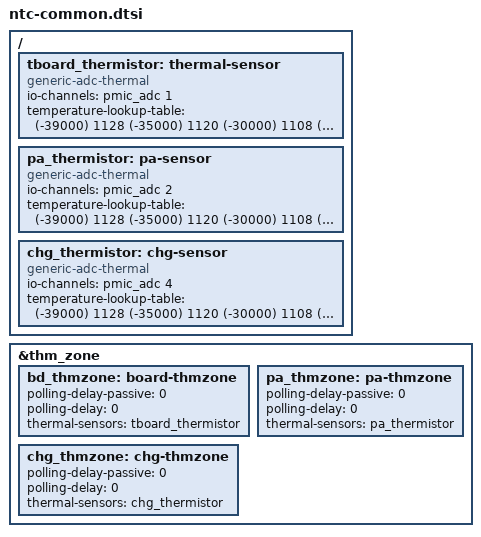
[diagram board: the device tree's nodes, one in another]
/ {
	tboard_thermistor:thermal-sensor {
		compatible = "generic-adc-thermal";
		#thermal-sensor-cells = <0>;
		io-channels = <&pmic_adc 1>;
		io-channel-names = "sensor-channel";
		temperature-lookup-table = <
					(-39000) 1128
					(-35000) 1120
					(-30000) 1108
					(-28000) 1103
					(-26000) 1097
					(-24000) 1089
					(-22000) 1082
					(-20000) 1073
					(-18000) 1064
					(-16000) 1054
					(-14000) 1043
					(-12000) 1032
					(-10000) 1019
					(-9000) 1012
					(-8000) 1005
					(-7000) 998
					(-6000) 990
					(-5000) 983
					(-4000) 975
					(-3000) 966
					(-2000) 957
					(-1000) 949
					0000 940
					1000 931
					2000 921
					3000 912
					4000 902
					5000 891
					6000 881
					7000 870
					8000 855
					9000 845
					10000 834
					11000 823
					12000 811
					13000 799
					14000 788
					15000 776
					16000 764
					17000 751
					18000 740
					19000 727
					20000 715
					21000 704
					22000 692
					23000 679
					24000 665
					25000 652
					26000 639
					27000 626
					28000 614
					29000 601
					30000 589
					31000 577
					32000 564
					33000 552
					34000 539
					35000 527
					36000 515
					37000 503
					38000 491
					39000 480
					40000 468
					41000 457
					42000 446
					43000 518
					44000 423
					45000 412
					46000 401
					47000 391
					48000 381
					49000 371
					50000 361
					51000 351
					52000 342
					53000 333
					54000 324
					55000 315
					56000 306
					57000 297
					58000 289
					59000 281
					60000 273
					61000 265
					62000 258
					63000 251
					64000 243
					65000 237
					66000 230
					67000 223
					68000 217
					69000 211
					70000 205
					74000 182
					78000 162
					82000 144
					86000 128
					90000 114
					94000 102
					98000 91
					102000 81
					106000 72
					110000 65
					114000 58
					118000 52
					122000 47
					125000 43 >;
	};

	pa_thermistor: pa-sensor {
		compatible = "generic-adc-thermal";
		#thermal-sensor-cells = <0>;
		io-channels = <&pmic_adc 2>;
		io-channel-names = "sensor-channel";
		temperature-lookup-table = <
					(-39000) 1128
					(-35000) 1120
					(-30000) 1108
					(-28000) 1103
					(-26000) 1097
					(-24000) 1089
					(-22000) 1082
					(-20000) 1073
					(-18000) 1064
					(-16000) 1054
					(-14000) 1043
					(-12000) 1032
					(-10000) 1019
					(-9000) 1012
					(-8000) 1005
					(-7000) 998
					(-6000) 990
					(-5000) 983
					(-4000) 975
					(-3000) 966
					(-2000) 957
					(-1000) 949
					0000 940
					1000 931
					2000 921
					3000 912
					4000 902
					5000 891
					6000 881
					7000 870
					8000 855
					9000 845
					10000 834
					11000 823
					12000 811
					13000 799
					14000 788
					15000 776
					16000 764
					17000 751
					18000 740
					19000 727
					20000 715
					21000 704
					22000 692
					23000 679
					24000 665
					25000 652
					26000 639
					27000 626
					28000 614
					29000 601
					30000 589
					31000 577
					32000 564
					33000 552
					34000 539
					35000 527
					36000 515
					37000 503
					38000 491
					39000 480
					40000 468
					41000 457
					42000 446
					43000 518
					44000 423
					45000 412
					46000 401
					47000 391
					48000 381
					49000 371
					50000 361
					51000 351
					52000 342
					53000 333
					54000 324
					55000 315
					56000 306
					57000 297
					58000 289
					59000 281
					60000 273
					61000 265
					62000 258
					63000 251
					64000 243
					65000 237
					66000 230
					67000 223
					68000 217
					69000 211
					70000 205
					74000 182
					78000 162
					82000 144
					86000 128
					90000 114
					94000 102
					98000 91
					102000 81
					106000 72
					110000 65
					114000 58
					118000 52
					122000 47
					125000 43 >;
	};

	chg_thermistor: chg-sensor {
		compatible = "generic-adc-thermal";
		#thermal-sensor-cells = <0>;
		io-channels = <&pmic_adc 4>;
		io-channel-names = "sensor-channel";
		temperature-lookup-table = <
					(-39000) 1128
					(-35000) 1120
					(-30000) 1108
					(-28000) 1103
					(-26000) 1097
					(-24000) 1089
					(-22000) 1082
					(-20000) 1073
					(-18000) 1064
					(-16000) 1054
					(-14000) 1043
					(-12000) 1032
					(-10000) 1019
					(-9000) 1012
					(-8000) 1005
					(-7000) 998
					(-6000) 990
					(-5000) 983
					(-4000) 975
					(-3000) 966
					(-2000) 957
					(-1000) 949
					0000 940
					1000 931
					2000 921
					3000 912
					4000 902
					5000 891
					6000 881
					7000 870
					8000 855
					9000 845
					10000 834
					11000 823
					12000 811
					13000 799
					14000 788
					15000 776
					16000 764
					17000 751
					18000 740
					19000 727
					20000 715
					21000 704
					22000 692
					23000 679
					24000 665
					25000 652
					26000 639
					27000 626
					28000 614
					29000 601
					30000 589
					31000 577
					32000 564
					33000 552
					34000 539
					35000 527
					36000 515
					37000 503
					38000 491
					39000 480
					40000 468
					41000 457
					42000 446
					43000 518
					44000 423
					45000 412
					46000 401
					47000 391
					48000 381
					49000 371
					50000 361
					51000 351
					52000 342
					53000 333
					54000 324
					55000 315
					56000 306
					57000 297
					58000 289
					59000 281
					60000 273
					61000 265
					62000 258
					63000 251
					64000 243
					65000 237
					66000 230
					67000 223
					68000 217
					69000 211
					70000 205
					74000 182
					78000 162
					82000 144
					86000 128
					90000 114
					94000 102
					98000 91
					102000 81
					106000 72
					110000 65
					114000 58
					118000 52
					122000 47
					125000 43 >;
	};

};

&thm_zone {
	bd_thmzone: board-thmzone {
		polling-delay-passive = <0>;
		polling-delay = <0>;
		thermal-sensors = <&tboard_thermistor>;
	};

	pa_thmzone: pa-thmzone {
		polling-delay-passive = <0>;
		polling-delay = <0>;
		thermal-sensors = <&pa_thermistor>;
	};

	chg_thmzone: chg-thmzone {
		polling-delay-passive = <0>;
		polling-delay = <0>;
		thermal-sensors = <&chg_thermistor>;
	};
};
